# STM32H523 register map
File version: 1.2
CPU: CM33 r0p0, little endian, MPU, FPU, 4 interrupt priority bits
Registers are 32-bit, read-write, reset 0x0 unless marked. A register's access mark holds for its fields unless they carry their own. Offsets are from the block's base; [hi:lo] are bit positions; {n}, {i} and the like mark numbered series; 'fields as' and 'values as' point back to an identical list.

## RTC — RTC register block
Base 0x44007800
Same registers: RTC_S 0x54007800
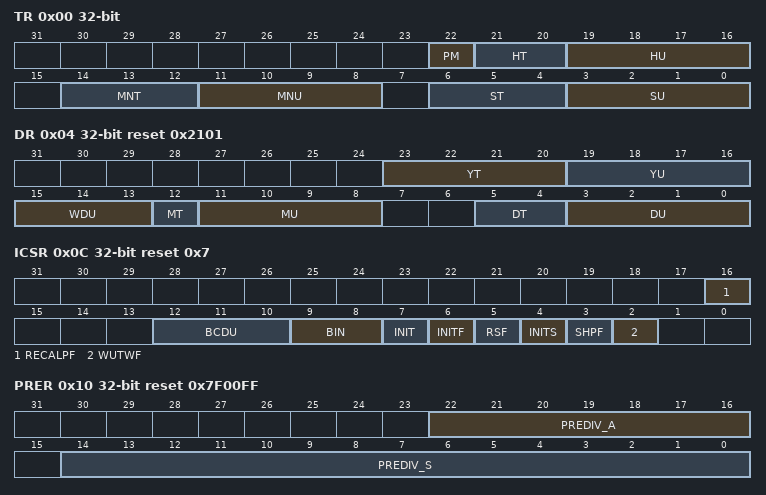
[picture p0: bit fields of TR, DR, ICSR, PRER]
0x00 TR — RTC time register
  [22] PM — AM/PM notation
    0=AM (AM or 24-hour format); 1=PM
  [21:20] HT — Hour tens in BCD format
  [19:16] HU — Hour units in BCD format
  [14:12] MNT — Minute tens in BCD format
  [11:8] MNU — Minute units in BCD format
  [6:4] ST — Second tens in BCD format
  [3:0] SU — Second units in BCD format
0x04 DR reset 0x2101 — RTC date register
  [23:20] YT — Year tens in BCD format
  [19:16] YU — Year units in BCD format
  [15:13] WDU range 1..7 — Week day units
  [12] MT — Month tens in BCD format
  [11:8] MU — Month units in BCD format
  [5:4] DT — Date tens in BCD format
  [3:0] DU — Date units in BCD format
0x08 SSR ro — RTC subsecond register
  [31:0] SS range 0..65535 — Synchronous binary counter
0x0C ICSR reset 0x7 — RTC initialization control and status register
  [16] RECALPF ro — Recalibration pending Flag
    1=Pending (The RECALPF status flag is automatically set to 1 when software writes to the RTC_CALR register, indicating that the RTC_CALR register is blocked. When the new calibration settings are taken into account, this bit returns to 0)
  [12:10] BCDU — BCD update (BIN = 10 or 11)
  [9:8] BIN — Binary mode
  [7] INIT — Initialization mode
    0=FreeRunningMode; 1=InitMode (Initialization mode used to program time and date register (RTC_TR and RTC_DR), and prescaler register (RTC_PRER). Counters are stopped and start counting from the new value when INIT is reset.)
  [6] INITF ro — Initialization flag
    0=NotAllowed (Calendar registers update is not allowed); 1=Allowed (Calendar registers update is allowed)
  [5] RSF write-0-clears — Registers synchronization flag
    on read: 0=NotSynced (Calendar shadow registers not yet synchronized); 1=Synced (Calendar shadow registers synchronized) | on write: 0=Clear (This flag is cleared by software by writing 0)
  [4] INITS ro — Initialization status flag
    0=NotInitalized (Calendar has not been initialized); 1=Initalized (Calendar has been initialized)
  [3] SHPF ro — Shift operation pending
    0=NoShiftPending (No shift operation is pending); 1=ShiftPending (A shift operation is pending)
  [2] WUTWF ro — Wake-up timer write flag
    0=UpdateNotAllowed (Wakeup timer configuration update not allowed); 1=UpdateAllowed (Wakeup timer configuration update allowed)
0x10 PRER reset 0x7F00FF — RTC prescaler register
  [22:16] PREDIV_A — Asynchronous prescaler factor
  [14:0] PREDIV_S — Synchronous prescaler factor
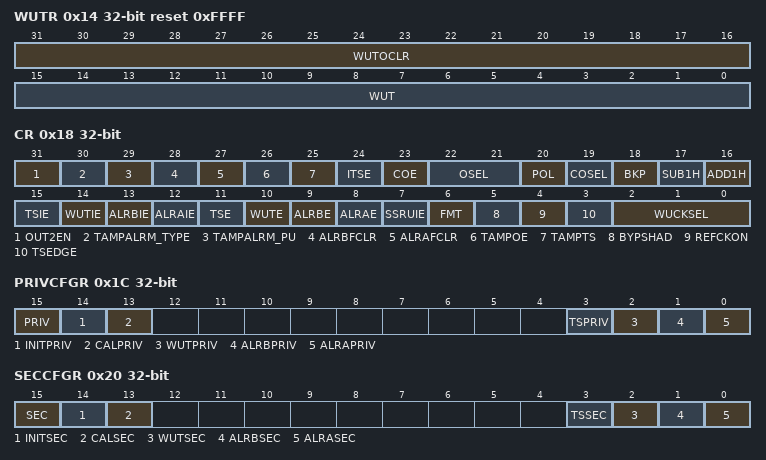
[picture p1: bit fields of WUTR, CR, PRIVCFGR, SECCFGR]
0x14 WUTR reset 0xFFFF — RTC wake-up timer register
  [31:16] WUTOCLR — Wake-up auto-reload output clear value
  [15:0] WUT — Wake-up auto-reload value bits
0x18 CR — RTC control register
  [31] OUT2EN — RTC_OUT2 output enable
    0=Disabled (RTC output 2 disable); 1=Enabled (RTC output 2 enable)
  [30] TAMPALRM_TYPE — TAMPALRM output type
    0=PushPull (TAMPALRM is push-pull output); 1=OpenDrain (TAMPALRM is open-drain output)
  [29] TAMPALRM_PU — TAMPALRM pull-up enable
    0=No pull-up is applied on TAMPALRM output; 1=PullUp (A pull-up is applied on TAMPALRM output)
  [28] ALRBFCLR — Alarm B flag automatic clear
  [27] ALRAFCLR — Alarm A flag automatic clear
  [26] TAMPOE — Tamper detection output enable on TAMPALRM
    0=Disabled (The tamper flag is not routed on TAMPALRM); 1=Enabled (The tamper flag is routed on TAMPALRM, combined with the signal provided by OSEL and with the polarity provided by POL)
  [25] TAMPTS — Activate timestamp on tamper detection event
    0=Disabled (Tamper detection event does not cause a RTC timestamp to be saved); 1=Enabled (Save RTC timestamp on tamper detection event)
  [24] ITSE — timestamp on internal event enable
    0=Disabled (Internal event timestamp disabled); 1=Enabled (Internal event timestamp enabled)
  [23] COE — Calibration output enable
    0=Disabled (Calibration output disabled); 1=Enabled (Calibration output enabled)
  [22:21] OSEL — Output selection
    0=Disabled (Output disabled); 1=Alarm A output enabled; 2=Alarm B output enabled; 3=Wakeup output enabled
  [20] POL — Output polarity
    0=High (The pin is high when ALRAF/ALRBF/WUTF is asserted (depending on OSEL[1:0])); 1=Low (The pin is low when ALRAF/ALRBF/WUTF is asserted (depending on OSEL[1:0]))
  [19] COSEL — Calibration output selection
    0=CalFreq_512Hz (Calibration output is 512 Hz (with default prescaler setting)); 1=CalFreq_1Hz (Calibration output is 1 Hz (with default prescaler setting))
  [18] BKP — Backup
    0=DSTNotChanged (Daylight Saving Time change has not been performed); 1=DSTChanged (Daylight Saving Time change has been performed)
  [17] SUB1H wo — Subtract 1 hour (winter time change)
    1=Sub1 (Subtracts 1 hour to the current time. This can be used for winter time change outside initialization mode)
  [16] ADD1H wo — Add 1 hour (summer time change)
    1=Add1 (Adds 1 hour to the current time. This can be used for summer time change outside initialization mode)
  [15] TSIE — Timestamp interrupt enable
    0=Disabled (Time-stamp Interrupt disabled); 1=Enabled (Time-stamp Interrupt enabled)
  [14] WUTIE — Wake-up timer interrupt enable
    0=Disabled (Wakeup timer interrupt disabled); 1=Enabled (Wakeup timer interrupt enabled)
  [12] ALR{x}IE (x=A,B; step 1) — Alarm {x} interrupt enable
    0=Disabled (Alarm Interrupt disabled); 1=Enabled (Alarm Interrupt enabled)
  [11] TSE — timestamp enable
    0=Disabled (Timestamp disabled); 1=Enabled (Timestamp enabled)
  [10] WUTE — Wake-up timer enable
    0=Disabled (Wakeup timer disabled); 1=Enabled (Wakeup timer enabled)
  [8] ALR{x}E (x=A,B; step 1) — Alarm {x} enable
    0=Disabled (Alarm disabled); 1=Enabled (Alarm enabled)
  [7] SSRUIE — SSR underflow interrupt enable
  [6] FMT — Hour format
    0=TwentyFourHour (24 hour/day format); 1=AM/PM hour format
  [5] BYPSHAD — Bypass the shadow registers
    0=ShadowReg (Calendar values (when reading from RTC_SSR, RTC_TR, and RTC_DR) are taken from the shadow registers, which are updated once every two RTCCLK cycles); 1=BypassShadowReg (Calendar values (when reading from RTC_SSR, RTC_TR, and RTC_DR) are taken directly from the calendar counters)
  [4] REFCKON — RTC_REFIN reference clock detection enable (50 or 60 Hz)
    0=Disabled (RTC_REFIN detection disabled); 1=Enabled (RTC_REFIN detection enabled)
  [3] TSEDGE — Timestamp event active edge
    0=RisingEdge (RTC_TS input rising edge generates a time-stamp event); 1=FallingEdge (RTC_TS input falling edge generates a time-stamp event)
  [2:0] WUCKSEL — ck_wut wake-up clock selection
    0=Div16 (RTC/16 clock is selected); 1=Div8 (RTC/8 clock is selected); 2=Div4 (RTC/4 clock is selected); 3=Div2 (RTC/2 clock is selected); 4=ClockSpare (ck_spre (usually 1 Hz) clock is selected); 6=ClockSpareWithOffset (ck_spre (usually 1 Hz) clock is selected and 2^16 is added to the WUT counter value)
0x1C PRIVCFGR — RTC privilege mode control register
  [15] PRIV — RTC privilege protection
  [14] INITPRIV — Initialization privilege protection
  [13] CALPRIV — Shift register, Delight saving, calibration and reference clock privilege protection
  [3] TSPRIV — Timestamp privilege protection
  [2] WUTPRIV — Wake-up timer privilege protection
  [1] ALRBPRIV — Alarm B privilege protection
  [0] ALRAPRIV — Alarm A and SSR underflow privilege protection
0x20 SECCFGR — RTC secure configuration register
  [15] SEC — RTC global protection
  [14] INITSEC — Initialization protection
  [13] CALSEC — Shift register, daylight saving, calibration and reference clock protection
  [3] TSSEC — Timestamp protection
  [2] WUTSEC — Wake-up timer protection
  [1] ALRBSEC — Alarm B protection
  [0] ALRASEC — Alarm A and SSR underflow protection
0x24 WPR wo — RTC write protection register
  [7:0] KEY — Write protection key
    0=Activate write protection (any value that is not the keys); 83=Deactivate2 (Key 2); 202=Deactivate1 (Key 1)
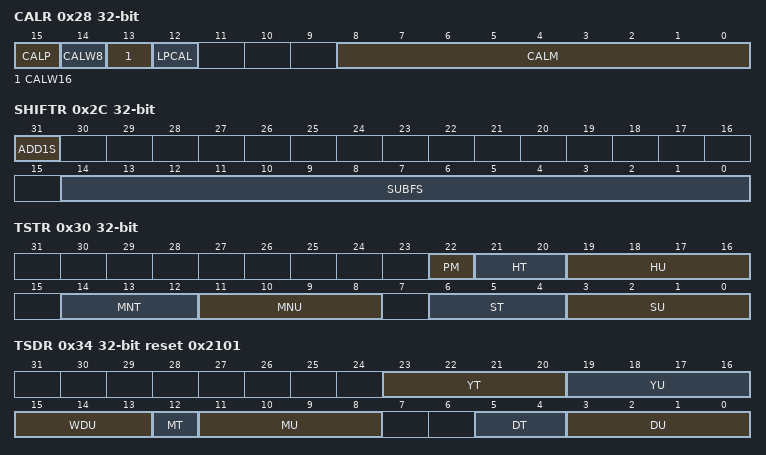
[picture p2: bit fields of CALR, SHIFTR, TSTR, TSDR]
0x28 CALR — RTC calibration register
  [15] CALP — Increase frequency of RTC by 488.
    0=NoChange (No RTCCLK pulses are added); 1=IncreaseFreq (One RTCCLK pulse is effectively inserted every 2^11 pulses (frequency increased by 488.5 ppm))
  [14] CALW8 — Use an 8-second calibration cycle period
    1=EightSeconds (When CALW8 is set to ‘1’, the 8-second calibration cycle period is selected)
  [13] CALW16 — Use a 16-second calibration cycle period
    1=SixteenSeconds (When CALW16 is set to ‘1’, the 16-second calibration cycle period is selected.This bit must not be set to ‘1’ if CALW8=1)
  [12] LPCAL — RTC low-power mode
  [8:0] CALM — Calibration minus
0x2C SHIFTR wo — RTC shift control register
  [31] ADD1S — Add one second
    1=Add1 (Add one second to the clock/calendar)
  [14:0] SUBFS — Subtract a fraction of a second
0x30 TSTR — RTC timestamp time register
  fields as TR
0x34 TSDR reset 0x2101 — RTC timestamp date register
  fields as DR
0x38 TSSSR ro — RTC timestamp subsecond register
  [31:0] SS range 0..65535 — Synchronous binary counter
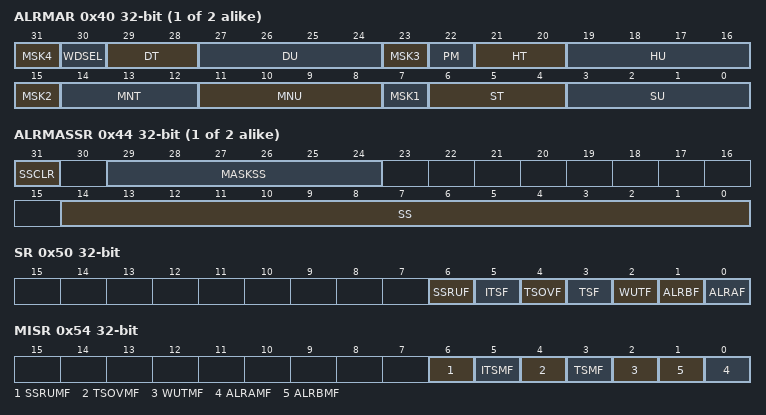
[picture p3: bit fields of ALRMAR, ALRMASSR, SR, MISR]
0x40 ALRM{x}R (x=A,B; step 0x8) — Alarm {x} register
  [31] MSK4 — Alarm date mask
    0=Mask (Alarm set if the date/day match); 1=NotMask (Date/day don’t care in Alarm comparison)
  [30] WDSEL — Week day selection
    0=DateUnits (DU[3:0] represents the date units); 1=WeekDay (DU[3:0] represents the week day. DT[1:0] is don’t care.)
  [29:28] DT — Date tens in BCD format
  [27:24] DU — Date units or day in BCD format
  [23] MSK3 — Alarm hours mask
    values as MSK4
  [22] PM — AM/PM notation
    0=AM (AM or 24-hour format); 1=PM
  [21:20] HT — Hour tens in BCD format
  [19:16] HU — Hour units in BCD format
  [15] MSK2 — Alarm minutes mask
    values as MSK4
  [14:12] MNT — Minute tens in BCD format
  [11:8] MNU — Minute units in BCD format
  [7] MSK1 — Alarm seconds mask
    values as MSK4
  [6:4] ST — Second tens in BCD format
  [3:0] SU — Second units in BCD format
0x44 ALRM{x}SSR (x=A,B; step 0x8) — Alarm {x} sub-second register
  [31] SSCLR — Clear synchronous counter on alarm (Binary mode only)
  [29:24] MASKSS — Mask the most-significant bits starting at this bit
  [14:0] SS — Subseconds value
0x50 SR ro — RTC status register
  [6] SSRUF — SSR underflow flag
  [5] ITSF — Internal timestamp flag
    1=TimestampEvent (This flag is set by hardware when a timestamp on the internal event occurs)
  [4] TSOVF — Timestamp overflow flag
    1=Overflow (This flag is set by hardware when a time-stamp event occurs while TSF is already set)
  [3] TSF — Timestamp flag
    1=TimestampEvent (This flag is set by hardware when a time-stamp event occurs)
  [2] WUTF — Wake-up timer flag
    1=Zero (This flag is set by hardware when the wakeup auto-reload counter reaches 0)
  [0] ALR{x}F (x=A,B; step 1) — Alarm {x} flag
    1=Match (This flag is set by hardware when the time/date registers (RTC_TR and RTC_DR) match the Alarm register (RTC_ALRxBR))
0x54 MISR ro — RTC nonsecure masked interrupt status register
  [6] SSRUMF — SSR underflow nonsecure masked flag
  [5] ITSMF — Internal timestamp nonsecure masked flag
    values as SR.ITSF
  [4] TSOVMF — Timestamp overflow nonsecure masked flag
    values as SR.TSOVF
  [3] TSMF — Timestamp nonsecure masked flag
    values as SR.TSF
  [2] WUTMF — Wake-up timer nonsecure masked flag
    values as SR.WUTF
  [0] ALR{x}MF (x=A,B; step 1) — Alarm {x} masked flag
    1=Match (This flag is set by hardware when the time/date registers (RTC_TR and RTC_DR) match the Alarm register (RTC_ALRMxR))
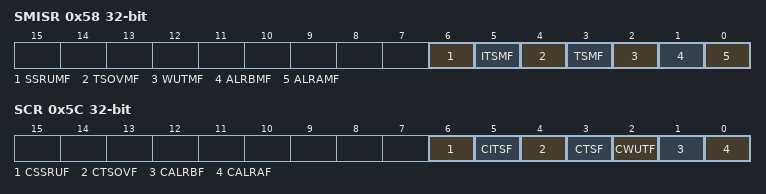
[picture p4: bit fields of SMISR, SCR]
0x58 SMISR ro — RTC secure masked interrupt status register
  [6] SSRUMF — SSR underflow secure masked flag
  [5] ITSMF — Internal timestamp interrupt secure masked flag
  [4] TSOVMF — Timestamp overflow interrupt secure masked flag
  [3] TSMF — Timestamp interrupt secure masked flag
  [2] WUTMF — Wake-up timer interrupt secure masked flag
  [1] ALRBMF — Alarm B interrupt secure masked flag
  [0] ALRAMF — Alarm A interrupt secure masked flag
0x5C SCR wo — RTC status clear register
  [all] fields
    1=Clear interrupt flag
  [6] CSSRUF — Clear SSR underflow flag
  [5] CITSF — Clear internal timestamp flag
  [4] CTSOVF — Clear timestamp overflow flag
  [3] CTSF — Clear timestamp flag
  [2] CWUTF — Clear wake-up timer flag
  [1] CALRBF — Clear alarm B flag
  [0] CALRAF — Clear alarm A flag
0x60 OR — RTC option register
  [0] OUT2_RMP — RTC_OUT2 mapping
0x70 ALR{x}BINR (x=A,B; step 0x4) — Alarm {x} binary mode register
  [31:0] SS — Synchronous counter alarm value in Binary mode
